# RA register map
Vendor: Renesas; Series: All Chips; File version: x.xx
Registers are 32-bit, read-write, reset 0x0 unless marked. A register's access mark holds for its fields unless they carry their own. Offsets are from the block's base; [hi:lo] are bit positions; lines under a group give offsets from that group; {n}, {i} and the like mark numbered series; 'fields as' and 'values as' point back to an identical list.

## R_PMISC — I/O Ports-MISC
Base 0x40040D00
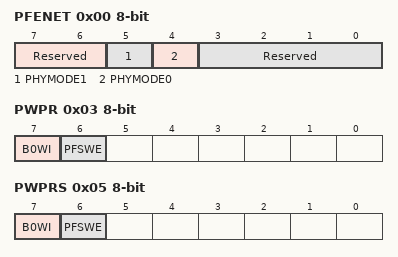
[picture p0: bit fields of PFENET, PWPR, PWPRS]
0x00 PFENET 8-bit — Ethernet Control Register
  [7:6] Reserved — These bits are read as 00. The write value should be 00.
  [5] PHYMODE1 — Ethernet Mode Setting ch1
    0=RMII mode (ETHERC channel 1); 1=MII mode (ETHERC channel 1)
  [4] PHYMODE0 — Ethernet Mode Setting ch0
    0=RMII mode (ETHERC channel 0); 1=MII mode (ETHERC channel 0)
  [3:0] Reserved — These bits are read as 0000. The write value should be 0000.
0x03 PWPR 8-bit reset not defined — Write-Protect Register
  [7] B0WI — PFSWE Bit Write Disable
    0=Writing to the PFSWE bit is enabled; other=Writing to the PFSWE bit is disabled
  [6] PFSWE — PmnPFS Register Write
    0=Writing to the PmnPFS register is disabled; 1=Writing to the PmnPFS register is enabled
0x05 PWPRS 8-bit reset not defined — Write-Protect Register for Secure
  fields as PWPR
{0x10+2i} PMSAR[{i}] (i=0..11) group — Port Security Attribution Register
  0x00 PMSAR 16-bit reset 0xFFFF — Port Security Attribution Register

## R_SRAM — SRAM
Base 0x40002000
0x00 PARIOAD 8-bit — SRAM Parity Error Operation After Detection Register
  [0] OAD — Operation after Detection
    1=Reset; 0=Non maskable interrupt
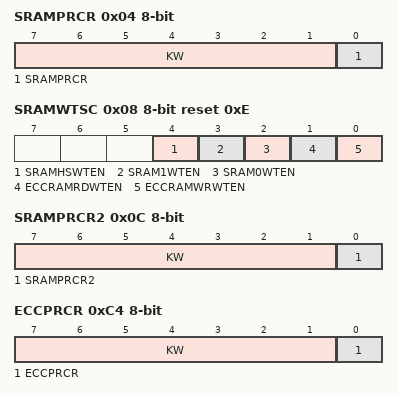
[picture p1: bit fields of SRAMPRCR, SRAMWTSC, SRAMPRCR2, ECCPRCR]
0x04 SRAMPRCR 8-bit — SRAM Protection Register
  [7:1] KW wo — Write Key Code
    120=Writing to the RAMPRCR bit is valid, when the KEY bits are written 1111000b; other=others (Writing to the RAMPRCR bit is invalid.)
  [0] SRAMPRCR — Register Write Control
    0=Disable writes to protected registers; 1=Enable writes to protected registers
0x08 SRAMWTSC 8-bit reset 0xE — RAM Wait State Control Register
  [4] SRAMHSWTEN — SRAMHS Wait Enable
    0=Not add wait state in read access cycle to SRAMHS; 1=Add wait state in read access cycle to SRAMHS
  [3] SRAM1WTEN — SRAM1 Wait Enable
    0=Not add wait state in read access cycle to SRAM1; 1=Add wait state in read access cycle to SRAM1
  [2] SRAM0WTEN — SRAM0 Wait Enable
    0=Not add wait state in read access cycle to SRAM0; 1=Add wait state in read access cycle to SRAM0
  [1] ECCRAMRDWTEN — ECCRAM Read wait enable
    0=Not add wait state in read access cycle to SRAM0 (ECC area); 1=Add wait state in read access cycle to SRAM0 (ECC area)
  [0] ECCRAMWRWTEN — ECCRAM Write Wait Enable
    0=Not add wait state in write access cycle to SRAM0 (ECC area); 1=Add wait state in write access cycle to SRAM0 (ECC area)
0x0C SRAMPRCR2 8-bit — SRAM Protection Register 2
  [7:1] KW wo — Write Key Code
  [0] SRAMPRCR2 — Register Write Control
    values as SRAMPRCR.SRAMPRCR
0xC0 ECCMODE 8-bit — ECC Operating Mode Control Register
  [1:0] ECCMOD — ECC Operating Mode Select
    0=Disable ECC function; 1=Setting prohibited; 2=Enable ECC function without error checking; 3=Enable ECC function with error checking
0xC1 ECC2STS 8-bit — ECC 2-Bit Error Status Register
  [0] ECC2ERR write-0-clears read-modifies — ECC 2-Bit Error Status
    0=No 2-bit ECC error occurred; 1=2-bit ECC error occurred
0xC2 ECC1STSEN 8-bit — ECC 1-Bit Error Information Update Enable Register
  [0] E1STSEN — ECC 1-Bit Error Information Update Enable
    0=Disables updating of the 1-bit ECC error information; 1=Enables updating of the 1-bit ECC error information
0xC3 ECC1STS 8-bit — ECC 1-Bit Error Status Register
  [0] ECC1ERR write-0-clears read-modifies — ECC 1-Bit Error Status
    0=No 1-bit ECC error occurred; 1=1-bit ECC error occurred
0xC4 ECCPRCR 8-bit — ECC Protection Register
  [7:1] KW wo — Write Key Code
    120=Writing to the ECCRAMPRCR bit is valid, when the KEY bits are written 1111000b; other=others (Writing to the ECCRAMPRCR bit is invalid.)
  [0] ECCPRCR — Register Write Control
    0=Disable writes to the protected registers; 1=Enable writes to the protected registers
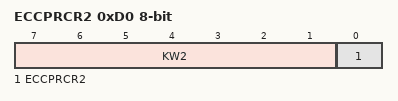
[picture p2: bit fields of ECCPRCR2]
0xD0 ECCPRCR2 8-bit — ECC Protection Register 2
  [7:1] KW2 wo — Write Key Code
    120=These bits enable or disable writes to the ECCPRCR2 bit; other=others (Writing to the ECCRAMPRCR2 bit is invalid.)
  [0] ECCPRCR2 — Register Write Control
    values as ECCPRCR.ECCPRCR
0xD4 ECCETST 8-bit — ECC Test Control Register
  [0] TSTBYP — ECC Bypass Select
    0=ECC bypass disabled; 1=ECC bypass enabled
0xD8 ECCOAD 8-bit — SRAM ECC Error Operation After Detection Register
  [0] OAD — Operation after Detection
    0=Non-maskable interrupt; 1=Reset
